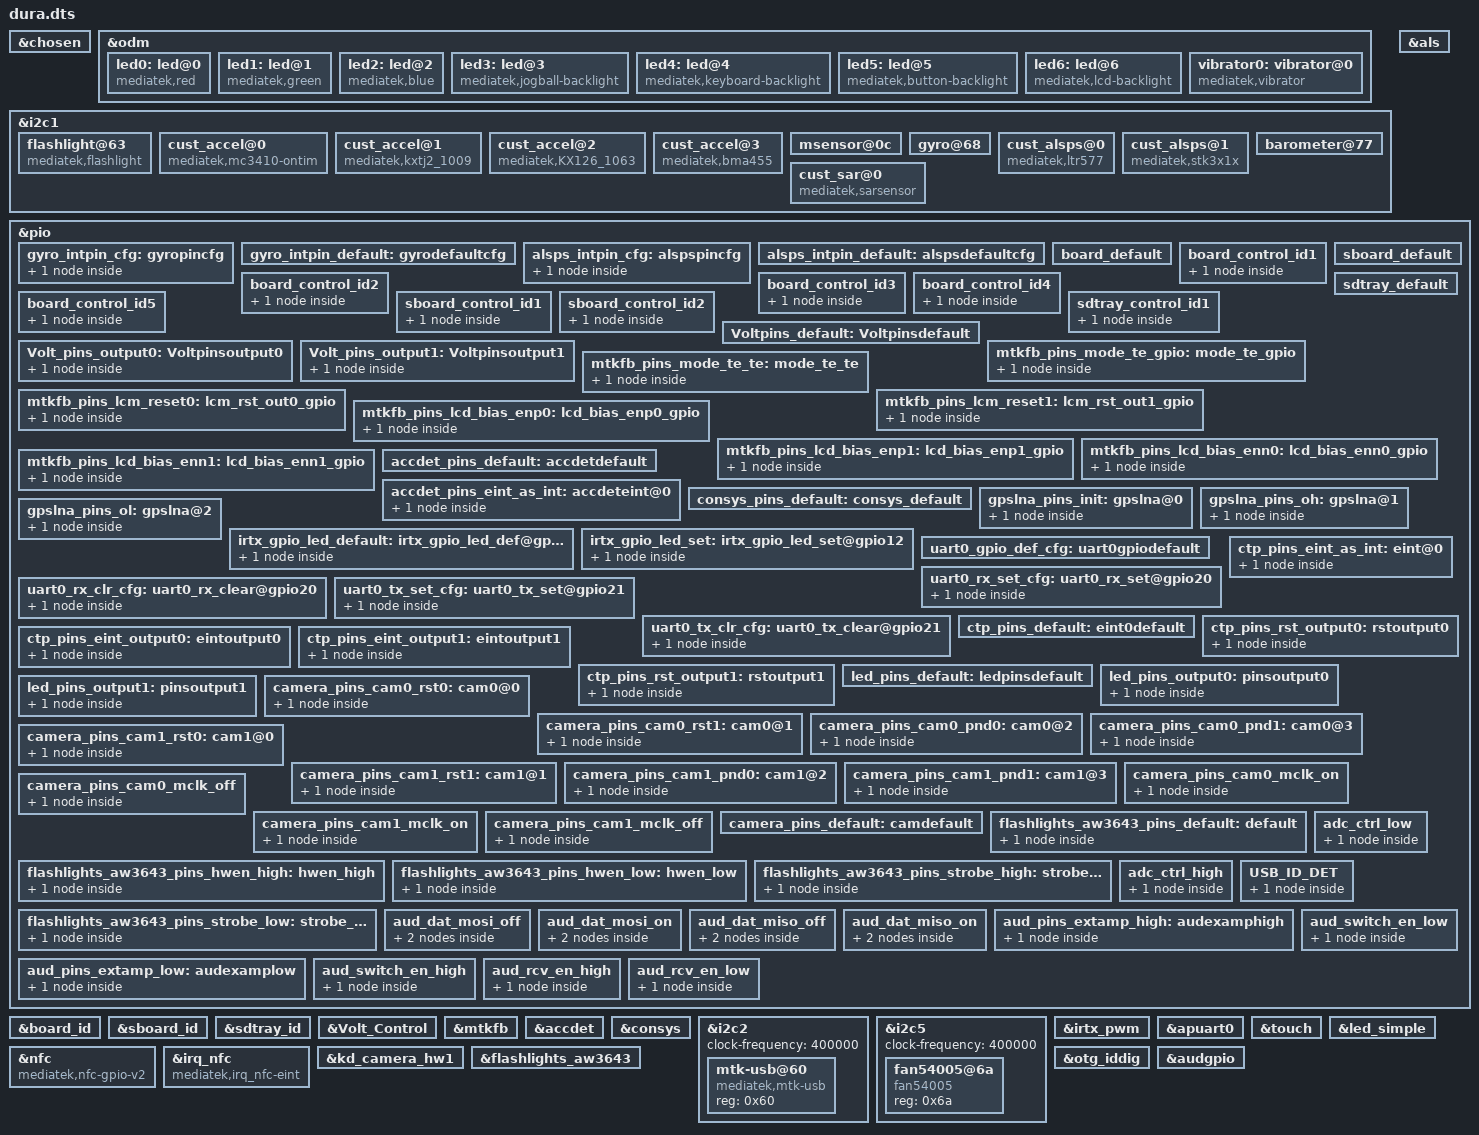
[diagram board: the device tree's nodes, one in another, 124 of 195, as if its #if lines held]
#include <generated/autoconf.h>
/dts-v1/;

#ifdef CONFIG_MTK_DTBO_FEATURE
/plugin/;
#include <dt-bindings/mmc/mt6739-msdc.h>
#include <dt-bindings/pinctrl/mt6739-pinfunc.h>
#else
#include "mt6739.dts"
#endif

/* chosen */
&chosen {
	bootargs = "console=tty0 console=ttyMT0,921600n1 root=/dev/ram initrd=0x44000000,\
0x1000000 loglevel=8 androidboot.selinux=permissive androidboot.hardware=mt6739 initcall_debug=1";
	/* fpga may has no lk, we need to specify display info here */
	/* fb buffer is reserved using this dts by memory node above */

	atag,videolfb-fb_base_l = <0x5e605000>;
	atag,videolfb-fb_base_h = <0>;
	atag,videolfb-islcmfound = <1>;
	atag,videolfb-islcm_inited = <0>;
	atag,videolfb-fps= <6000>;
	atag,videolfb-vramSize= <0x017bb000>;
	atag,videolfb-lcmname= "nt35521_hd_dsi_vdo_truly_nt50358_drv";
};

&odm {
	led0:led@0 {
		compatible = "mediatek,red";
		led_mode = <3>;
		data = <1>;
		pwm_config = <0 0 0 0 0>;
	};
	led1:led@1 {
		compatible = "mediatek,green";
		led_mode = <3>;
		data = <2>;
		pwm_config = <0 0 0 0 0>;
	};
	led2:led@2 {
		compatible = "mediatek,blue";
		led_mode = <0>;
		data = <1>;
		pwm_config = <0 0 0 0 0>;
	};
	led3:led@3 {
		compatible = "mediatek,jogball-backlight";
		led_mode = <0>;
		data = <1>;
		pwm_config = <0 0 0 0 0>;
	};
	led4:led@4 {
		compatible = "mediatek,keyboard-backlight";
		led_mode = <0>;
		data = <1>;
		pwm_config = <0 0 0 0 0>;
	};
	led5:led@5 {
		compatible = "mediatek,button-backlight";
		led_mode = <0>;
		data = <1>;
		pwm_config = <0 0 0 0 0>;
	};
	led6:led@6 {
		compatible = "mediatek,lcd-backlight";
		led_mode = <4>;
		data = <1>;
		pwm_config = <0 0 0 0 0>;
	};
	vibrator0:vibrator@0 {
		compatible = "mediatek,vibrator";
		vib_timer = <25>;
		vib_limit = <9>;
		vib_vol= <11>;
	};
};

&i2c1 {
    flashlight@63 {
		compatible				= "mediatek,flashlight";
		i2c_num				= <1>;
		i2c_addr				= <0x63>;
		};
/*  start sensor */
    cust_accel@0 {
		compatible				= "mediatek,mc3410-ontim";
		i2c_num				= <1>;
		i2c_addr				= <0x4c 0 0 0>;
		direction				= <6>;
		power_id				= <0xffff>;
		power_vol				= <0>;
		firlen					= <0>;
		is_batch_supported			= <0>;
 		calib_enable			= <1>;
		auto_calib_enable			= <0>;
		};
	cust_accel@1 {
        	compatible = "mediatek,kxtj2_1009";
        	i2c_num = <1>;
        	/* i2c_addr = <0x4c 0 0 0>; */
                direction = <4>;
        	power_id = <0xffff>;
        	power_vol = <0>;
        	firlen = <0>;
        	is_batch_supported = <0>;
		calib_enable                    = <1>;
                auto_calib_enable                       = <0>;
        	};
	cust_accel@2 {
                compatible = "mediatek,KX126_1063";
                i2c_num = <1>;
                //i2c_addr = <0x4c 0 0 0>;
                direction = <4>;
                power_id = <0xffff>;
                power_vol = <0>;
                firlen = <0>;
                is_batch_supported = <0>;
        };
	cust_accel@3 {
                compatible = "mediatek,bma455";
                i2c_num = <1>;
                //i2c_addr = <0x4c 0 0 0>;
                direction = <4>;
                power_id = <0xffff>;
                power_vol = <0>;
                firlen = <0>;
                is_batch_supported = <0>;
        	};

	msensor@0c {
		i2c_num = <1>;
		i2c_addr = <0x0d 0 0 0>;
		direction = <8>;
		power_id = <0xffff>;
		power_vol = <0>;
		is_batch_supported = <0>;
	};

	gyro@68 {
		pinctrl-names = "pin_default", "pin_cfg";
		pinctrl-0 = <&gyro_intpin_default>;
		pinctrl-1 = <&gyro_intpin_cfg>;
		i2c_num = <1>;
		i2c_addr = <0x68 0 0 0>;
		direction = <5>;
		power_id = <0xffff>;
		power_vol = <0>;
		firlen = <0>;
		is_batch_supported = <0>;
	};
/*
	alsps@51 {
		pinctrl-names = "pin_default", "pin_cfg";
		pinctrl-0 = <&alsps_intpin_default>;
		pinctrl-1 = <&alsps_intpin_cfg>;
		status = "okay";
		//customization 
		i2c_num = <1>;
		i2c_addr = <0x51 0 0 0>;
		polling_mode_ps = <0>;
		polling_mode_als = <1>;
		power_id = <0xffff>;
		power_vol = <0>;
		als_level = <0 328 861 1377 3125 7721 7767 12621 23062 28430 33274 47116 57694 57694 65535>;
		als_value = <0 133 304 502 1004 2005 3058 5005 8008 10010 12000 16000 20000 20000 20000 20000>;
		ps_threshold_high = <26>;
		ps_threshold_low = <21>;
		is_batch_supported_ps = <0>;
		is_batch_supported_als = <0>;
	};*/

	cust_alsps@0 {
	
		compatible				= "mediatek,ltr577";

		i2c_num	= <1>;
		i2c_addr = <0x53 0 0 0>;
		polling_mode_ps	= <0>;
		polling_mode_als = <1>;
		power_id				= <0xffff>;
		power_vol				= <0>;
		als_level = <  
					0  5   25	52	 102  258  512	650 1000	2000  5000   10000
					0  5   25	52	 102  258  512	650 1000	2000  5000   10000
					0  2   10	20	 40   100  200	310 400	800   2000   4000
					0  11  56	114	 218  546  1109  1610 2000	4000  10000  20000
					0  10  46	100	 192  500  1146 1720 2566	5000  13000  26000
					0  10  57	115	 226  586  1093 1680 2200	4533  10000  20000
					0  10  50	100	 200  500  1000 1600 2000	4000  10000  20000
					0  10  47	81	 170  445  979	1620 2103	3263  10000  20000
					0  10  50	107	 200  480  1000 1600 2000	4000  10000  20000
					 >;
		als_value = < 0  10  50  100  200  500   1000  1600 2000  4000  10000  20000 >;
		ps_threshold_high		=  <900>;
		ps_threshold_low		=  <700>;
		is_batch_supported_ps	= <0>;
		is_batch_supported_als	= <0>;
		};

	cust_alsps@1 {
		compatible				= "mediatek,stk3x1x";
		i2c_num				= <1>;
		i2c_addr				= <0x48 0 0 0>;
		polling_mode_ps			= <0>;
		polling_mode_als		= <1>;
		power_id				= <0xffff>;
		power_vol				= <0>;
		als_level = < 
					0  11  48  97   197  389  481   765   959  1430  1500  2877
					0  12  58  119  223  449  577   963  1169  2116  2829  3507
					0  13  67  137  287  554  690  1065  1317  2015  2635  3951
					0  13  49  101  201  393  490   780   963  1463  1544  2889
					0  12  57  108  222  462  610   964  1185  2053  2749  3555
					0  14  67  143  298  587  719  1155  1405  2137  2732  4215
					0  11  45   92  181  359  448   712   885  1280  1354  2655
					0  12  57  109  201  408  535   894  1085  1761  2355  3255
					0  12  64  137  283  561  684  1043  1272  1998  2499  3816
					>;
		als_value = <0  10  50  100  200  400  500   800  1000  1600  2000  3000>;
		state_val		=  <0>;
		psctrl_val		=  <0x31>;
		alsctrl_val	= <0x39>;
		ledctrl_val	= <0xFF>;
		wait_val		= <0xF>;
		ps_threshold_high		=  <900>;
		ps_threshold_low		=  <700>;
		is_batch_supported_ps	= <0>;
		is_batch_supported_als	= <0>;
		};

	barometer@77 {
		i2c_num = <1>;
		i2c_addr = <0x77 0 0 0>;
		direction = <0>;
		power_id = <0xffff>;
		power_vol = <0>;
		firlen = <32>;
		is_batch_supported = <0>;
	};
	cust_sar@0 {
		compatible				= "mediatek,sarsensor";
		i2c_num				= <1>;
		i2c_addr				= <0x28 0 0 0>;
		};
/* end sensor */
};

&als {
		pinctrl-names = "pin_default", "pin_cfg";
		pinctrl-0 = <&alsps_intpin_default>;
		pinctrl-1 = <&alsps_intpin_cfg>;
		status = "okay";
};
/* sensor gpio standization */
&pio {

	gyro_intpin_cfg: gyropincfg {

	    pins_cmd_dat {
			pins = <PINMUX_GPIO5__FUNC_GPIO5>;
			slew-rate = <0>;
			bias-pull-down = <00>;
		};
	};

	gyro_intpin_default: gyrodefaultcfg {

	};
};

&pio {
	alsps_intpin_cfg: alspspincfg {

		pins_cmd_dat {
			pins = <PINMUX_GPIO1__FUNC_GPIO1>;
			slew-rate = <0>;
			bias-pull-up = <MTK_PUPD_SET_R1R0_01>;
		};
	};

	alsps_intpin_default: alspsdefaultcfg {

	};
};

/* sensor end */
/*Board start*/
&board_id{
id1,intr_gpio = <&pio 121 0x0>;
id2,intr_gpio = <&pio 54 0x0>;
id3,intr_gpio = <&pio 53 0x0>;
id4,intr_gpio = <&pio 5 0x0>;
id5,intr_gpio = <&pio 11 0x0>;
pinctrl-names = "default", "board_id1", "board_id2","board_id3","board_id4","board_id5";
	pinctrl-0 = <&board_default>;
	pinctrl-1 = <&board_control_id1>;
	pinctrl-2 = <&board_control_id2>;
	pinctrl-3 = <&board_control_id3>;
	pinctrl-4 = <&board_control_id4>;
	pinctrl-5 = <&board_control_id5>;
	status = "okay";
};

/* Board GPIO standardization */
&pio {
	board_default: board_default {

    };

	board_control_id1: board_control_id1 {
		pins_cmd_dat {
			pins = <PINMUX_GPIO121__FUNC_GPIO121>;
			slew-rate = <0>;
			bias-disable;
        };
    };

	board_control_id2: board_control_id2 {
		pins_cmd_dat {
			pins = <PINMUX_GPIO54__FUNC_GPIO54>;
			slew-rate = <0>;
			bias-disable;
        };
    };

	board_control_id3: board_control_id3 {
		pins_cmd_dat {
			pins = <PINMUX_GPIO53__FUNC_GPIO53>;
			slew-rate = <0>;
			bias-disable;
        };
    };

	board_control_id4: board_control_id4 {
		pins_cmd_dat {
			pins = <PINMUX_GPIO5__FUNC_GPIO5>;
			slew-rate = <0>;
			bias-disable;
        };
    };

	board_control_id5: board_control_id5 {
		pins_cmd_dat {
			pins = <PINMUX_GPIO11__FUNC_GPIO11>;
			slew-rate = <0>;
			bias-disable;
        };
    };
};
/* Board end */

/*SubBoard start*/
&sboard_id{
sub1,intr_gpio = <&pio 93 0x0>;
sub2,intr_gpio = <&pio 92 0x0>;
pinctrl-names = "default", "sboard_id1", "sboard_id2";
	pinctrl-0 = <&sboard_default>;
	pinctrl-1 = <&sboard_control_id1>;
	pinctrl-2 = <&sboard_control_id2>;
	status = "okay";
};

/* Sub_Board GPIO standardization */
&pio {
	sboard_default: sboard_default {

    };

	sboard_control_id1: sboard_control_id1 {
		pins_cmd_dat {
			pins = <PINMUX_GPIO93__FUNC_GPIO93>;
			slew-rate = <0>;
			bias-disable;
        };
    };

	sboard_control_id2:sboard_control_id2 {
		pins_cmd_dat {
			pins = <PINMUX_GPIO92__FUNC_GPIO92>;
			slew-rate = <0>;
			bias-disable;
        };
    };

};
/* SubBoard end */

/*sdtray start*/
&sdtray_id{
sdtray1,intr_gpio = <&pio 15 0x0>;
pinctrl-names = "default","sdtray_id1";
	pinctrl-0 = <&sdtray_default>;
	pinctrl-1 = <&sdtray_control_id1>;
	status = "okay";
};

&pio {
	sdtray_default:sdtray_default{

	};
	sdtray_control_id1:sdtray_control_id1{
		pins_cmd_dat {
			pins = <PINMUX_GPIO15__FUNC_GPIO15>;
			slew-rate = <0>;
			bias-disable;
		};
	};
};
/*sdtray end*/

/*Voltage Control Start*/
&Volt_Control{
	pinctrl-names = "default","Volt_output0","Volt_output1";
	pinctrl-0 = <&Voltpins_default>;
	pinctrl-1 = <&Volt_pins_output0>;
	pinctrl-2 = <&Volt_pins_output1>;
	status = "okay";
};

&pio {
	Voltpins_default: Voltpinsdefault {
	};
	Volt_pins_output0: Voltpinsoutput0 {
		pins_cmd_dat {
			pins = <PINMUX_GPIO95__FUNC_GPIO95>;
			slew_rate = <1>;
			output-low;
		};
	};
	Volt_pins_output1: Voltpinsoutput1 {
		pins_cmd_dat {
			pins = <PINMUX_GPIO95__FUNC_GPIO95>;
			slew_rate = <1>;
			output-high;
		};
	};
};
/*Voltage Control End*/
/* DISPSYS GPIO standardization */
&pio {
	mtkfb_pins_mode_te_gpio: mode_te_gpio {
		pins_cmd_dat {
			pins = <PINMUX_GPIO84__FUNC_DSI_TE>;
		};
	};

	mtkfb_pins_mode_te_te: mode_te_te {
		pins_cmd_dat {
			pins = <PINMUX_GPIO84__FUNC_DSI_TE>;
		};
	};

	mtkfb_pins_lcm_reset0: lcm_rst_out0_gpio {
		pins_cmd_dat {
			pins = <PINMUX_GPIO83__FUNC_GPIO83>;
			slew-rate = <1>;
			output-low;
		};
	};

	mtkfb_pins_lcm_reset1: lcm_rst_out1_gpio {
		pins_cmd_dat {
			pins = <PINMUX_GPIO83__FUNC_GPIO83>;
			slew-rate = <1>;
			output-high;
		};
	};

	mtkfb_pins_lcd_bias_enp0: lcd_bias_enp0_gpio {
		pins_cmd_dat {
			pins = <PINMUX_GPIO122__FUNC_GPIO122>;
			slew-rate = <1>;
			output-low;
		};
	};
	mtkfb_pins_lcd_bias_enp1: lcd_bias_enp1_gpio {
		pins_cmd_dat {
			pins = <PINMUX_GPIO122__FUNC_GPIO122>;
			slew-rate = <1>;
			output-high;
		};
	};
	mtkfb_pins_lcd_bias_enn0: lcd_bias_enn0_gpio {
		pins_cmd_dat {
			pins = <PINMUX_GPIO112__FUNC_GPIO112>;
			slew-rate = <1>;
			output-low;
		};
	};
	mtkfb_pins_lcd_bias_enn1: lcd_bias_enn1_gpio {
		pins_cmd_dat {
			pins = <PINMUX_GPIO112__FUNC_GPIO112>;
			slew-rate = <1>;
			output-high;
		};
	};

};

&mtkfb {
	pinctrl-names = "mode_te_gpio", "mode_te_te", "lcm_rst_out0_gpio",
		"lcm_rst_out1_gpio", "lcd_bias_enp0_gpio", "lcd_bias_enp1_gpio", "lcd_bias_enn0_gpio", "lcd_bias_enn1_gpio";
	pinctrl-0 = <&mtkfb_pins_mode_te_gpio>;
	pinctrl-1 = <&mtkfb_pins_mode_te_te>;
	pinctrl-2 = <&mtkfb_pins_lcm_reset0>;
	pinctrl-3 = <&mtkfb_pins_lcm_reset1>;
	pinctrl-4 = <&mtkfb_pins_lcd_bias_enp0>;
	pinctrl-5 = <&mtkfb_pins_lcd_bias_enp1>;
	pinctrl-6 = <&mtkfb_pins_lcd_bias_enn0>;
	pinctrl-7 = <&mtkfb_pins_lcd_bias_enn1>;
	status = "okay";
};
/* DISPSYS GPIO standardization end */


/* accdet start */
&accdet {
	/* accdet micbias voltage: 0x07,2.7v;0x05,2.5v;0x02,1.9v */
	accdet-mic-vol = <7>;
	headset-mode-setting = <0x500 0x500 1 0x1f0 0x800 0x800 0x20 0x44>;
	accdet-plugout-debounce = <1>;
	/*1:ACC mode, 2:low cost without in bias, 6:low cost with in bias*/
	accdet-mic-mode = <1>;
	/* eint_level_trigger: 8,LEVEL_LOW(default);4,LEVEL_HIGH;others,LEVEL_LOW */
	headset-eint-level-pol = <8>;
	/*0--MD_MAX--UP_MAX--DW_MAX*/
	headset-three-key-threshold = <0 80 220 447>;
	headset-three-key-threshold-CDD = <0 121 192 600>;
	/*0--MD_MAX--VOICE_MAX--UP_MAX--DW_MAX*/
	headset-four-key-threshold = <0 58 121 192 400>;
	/* ACCDET GPIO standardization ACC mode no use */
	pinctrl-names = "default", "state_eint_as_int";
	pinctrl-0 = <&accdet_pins_default>;
	pinctrl-1 = <&accdet_pins_eint_as_int>;
	status = "okay";
};
&pio {
	accdet_pins_default: accdetdefault {
	};
	accdet_pins_eint_as_int: accdeteint@0 {
		pins_cmd_dat {
			/*pins = <PINMUX_GPIO11__FUNC_GPIO11>;*/
			slew-rate = <0>;
			bias-disable;
		};
	};
};
/* accdet end */
/* CONSYS GPIO standardization */
&pio {
	consys_pins_default: consys_default {
	};
	gpslna_pins_init: gpslna@0 {
		pins_cmd_dat {
			pins = <PINMUX_GPIO118__FUNC_GPIO118>;
			slew-rate = <0>;
			bias-disable;
			output-low;
		};
	};
	gpslna_pins_oh: gpslna@1 {
		pins_cmd_dat {
			pins = <PINMUX_GPIO118__FUNC_GPIO118>;
			slew-rate = <1>;
			output-high;
		};
	};
	gpslna_pins_ol: gpslna@2 {
		pins_cmd_dat {
			pins = <PINMUX_GPIO118__FUNC_GPIO118>;
			slew-rate = <1>;
			output-low;
		};
	};
};
&consys {
	pinctrl-names = "default", "gps_lna_state_init", "gps_lna_state_oh", "gps_lna_state_ol";
	pinctrl-0 = <&consys_pins_default>;
	pinctrl-1 = <&gpslna_pins_init>;
	pinctrl-2 = <&gpslna_pins_oh>;
	pinctrl-3 = <&gpslna_pins_ol>;
	status = "okay";
};
&i2c2 {
	#address-cells = <1>;
	#size-cells = <0>;
	clock-frequency = <400000>;

	mtk-usb@60 {
		compatible = "mediatek,mtk-usb";
		reg = <0x60>;
		status = "okay";
	};
};
&i2c5 {
	#address-cells = <1>;
	#size-cells = <0>;
	clock-frequency = <400000>;

	fan54005@6a {
		compatible = "fan54005";
		reg = <0x6a>;
		status = "okay";
	};
};

/* IRTX GPIO Start */
&irtx_pwm {
	pinctrl-names = "irtx_gpio_led_default", "irtx_gpio_led_set";
	pinctrl-0 = <&irtx_gpio_led_default>;
	pinctrl-1 = <&irtx_gpio_led_set>;
	status = "okay";
};
&pio {
	/* IRTX GPIO Settings -Start */
	/* default: GPIO0, output, high */
	irtx_gpio_led_default:irtx_gpio_led_def@gpio12 {
		pins_cmd_dat {
			pins = <PINMUX_GPIO12__FUNC_GPIO12>;
			slew-rate = <1>;
			bias-disable;
			output-low;
			input-schmitt-enable = <0>;
		};
	};

	irtx_gpio_led_set:irtx_gpio_led_set@gpio12 {
		pins_cmd_dat {
			pins = <PINMUX_GPIO12__FUNC_PWM1>;
			slew-rate = <1>;
			output-high;
		};
	};
}; /* IRTX GPIO Settings -End */

/* UART GPIO */
&apuart0 {
	pinctrl-names = "uart0_gpio_default",
			"uart0_rx_set",
			"uart0_rx_clear",
			"uart0_tx_set",
			"uart0_tx_clear";
	pinctrl-0 = <&uart0_gpio_def_cfg>;
	pinctrl-1 = <&uart0_rx_set_cfg>;
	pinctrl-2 = <&uart0_rx_clr_cfg>;
	pinctrl-3 = <&uart0_tx_set_cfg>;
	pinctrl-4 = <&uart0_tx_clr_cfg>;
	status = "okay";
};

&pio {
	/* UART GPIO Settings - Start */
	/* UART0: rx set, rx clear, tx clear, tx clear*/
	uart0_gpio_def_cfg:uart0gpiodefault {

	};
	uart0_rx_set_cfg:uart0_rx_set@gpio20 {
		pins_cmd_dat {
			pins = <PINMUX_GPIO20__FUNC_UART0RX>;
		};
	};
	uart0_rx_clr_cfg:uart0_rx_clear@gpio20 {
		pins_cmd_dat {
			pins = <PINMUX_GPIO20__FUNC_GPIO20>;
			slew-rate = <1>;
			output-high;
		};
	};
	uart0_tx_set_cfg:uart0_tx_set@gpio21 {
		pins_cmd_dat {
			pins = <PINMUX_GPIO21__FUNC_UART0TX>;
		};
	};
	uart0_tx_clr_cfg:uart0_tx_clear@gpio21 {
		pins_cmd_dat {
			pins = <PINMUX_GPIO21__FUNC_GPIO21>;
			slew-rate = <1>;
			output-high;
		};
	};
};/* UART GPIO end */

/* TOUCH start */
&touch {
	tpd-resolution = <720 1280>;
	use-tpd-button = <0>;
	tpd-key-num = <3>;
	tpd-key-local= <139 172 158 0>;
	tpd-key-dim-local = <90 883 100 40 230 883 100 40 370 883 100 40 0 0 0 0>;
	tpd-max-touch-num = <5>;
	tpd-filter-enable = <1>;
	tpd-filter-pixel-density = <106>;
	tpd-filter-custom-prameters = <0 0 0 0 0 0 0 0 0 0 0 0>;
	tpd-filter-custom-speed = <0 0 0>;
	pinctrl-names = "default", "state_eint_as_int", "state_eint_output0", "state_eint_output1",
		"state_rst_output0", "state_rst_output1";
	pinctrl-0 = <&ctp_pins_default>;
	pinctrl-1 = <&ctp_pins_eint_as_int>;
	pinctrl-2 = <&ctp_pins_eint_output0>;
	pinctrl-3 = <&ctp_pins_eint_output1>;
	pinctrl-4 = <&ctp_pins_rst_output0>;
	pinctrl-5 = <&ctp_pins_rst_output1>;
	status = "okay";
};
&pio {
	ctp_pins_default: eint0default {
	};
	ctp_pins_eint_as_int: eint@0 {
		pins_cmd_dat {
			pins = <PINMUX_GPIO6__FUNC_GPIO6>;
			slew-rate = <0>;
			bias-disable;
		};
	};
	ctp_pins_eint_output0: eintoutput0 {
		pins_cmd_dat {
			pins = <PINMUX_GPIO6__FUNC_GPIO6>;
			slew-rate = <1>;
			output-low;
		};
	};
	ctp_pins_eint_output1: eintoutput1 {
		pins_cmd_dat {
			pins = <PINMUX_GPIO6__FUNC_GPIO6>;
			slew-rate = <1>;
			output-high;
		};
	};
	ctp_pins_rst_output0: rstoutput0 {
		pins_cmd_dat {
			pins = <PINMUX_GPIO119__FUNC_GPIO119>;
			slew-rate = <1>;
			output-low;
		};
	};
	ctp_pins_rst_output1: rstoutput1 {
		pins_cmd_dat {
			pins = <PINMUX_GPIO119__FUNC_GPIO119>;
			slew-rate = <1>;
			output-high;
		};
	};
};
/* TOUCH end */
/* leds start */
&led_simple {
	pinctrl-names = "default", "led_output0", "led_output1";
	pinctrl-0 = <&led_pins_default>;
	pinctrl-1 = <&led_pins_output0>;
	pinctrl-2 = <&led_pins_output1>;
	status = "okay";
};
&pio {
	led_pins_default: ledpinsdefault {
	};
	led_pins_output0: pinsoutput0 {
		pins_cmd_dat {
			pins = <PINMUX_GPIO94__FUNC_GPIO94>;
			slew-rate = <1>;
			output-low;
		};
	};
	led_pins_output1: pinsoutput1 {
		pins_cmd_dat {
			pins = <PINMUX_GPIO94__FUNC_GPIO94>;
			slew-rate = <1>;
			output-high;
		};
	};
};
/* leds end */
/* NFC start */
&nfc {
	compatible = "mediatek,nfc-gpio-v2";
	gpio-rst = <7>;
	gpio-rst-std = <&pio 7 0x0>;
	gpio-irq = <14>;
	gpio-irq-std = <&pio 14 0x0>;
};

&irq_nfc {
	compatible = "mediatek,irq_nfc-eint";
};
/* NFC end */

/* CAMERA GPIO standardization */
&pio {
	camera_pins_cam0_rst0: cam0@0 {
		pins_cmd_dat {
			pins = <PINMUX_GPIO29__FUNC_GPIO29>;
			slew-rate = <1>; /*direction 0:in, 1:out*/
			output-low;/*direction out used only. output_low or high*/
		};
	};
	camera_pins_cam0_rst1: cam0@1 {
		pins_cmd_dat {
			pins = <PINMUX_GPIO29__FUNC_GPIO29>;
			slew-rate = <1>;
			output-high;
		};
	};
	camera_pins_cam0_pnd0: cam0@2 {
		pins_cmd_dat {
			pins = <PINMUX_GPIO30__FUNC_GPIO30>;
			slew-rate = <1>;
			output-low;
		};
	};
	camera_pins_cam0_pnd1: cam0@3 {
		pins_cmd_dat {
			pins = <PINMUX_GPIO30__FUNC_GPIO30>;
			slew-rate = <1>;
			output-high;
		};
	};
	camera_pins_cam1_rst0: cam1@0 {
		pins_cmd_dat {
			pins = <PINMUX_GPIO22__FUNC_GPIO22>;
			slew-rate = <1>; /*direction 0:in, 1:out*/
			output-low;/*direction out used only. output_low or high*/
		};
	};
	camera_pins_cam1_rst1: cam1@1 {
		pins_cmd_dat {
			pins = <PINMUX_GPIO22__FUNC_GPIO22>;
			slew-rate = <1>;
			output-high;
		};
	};
	camera_pins_cam1_pnd0: cam1@2 {
		pins_cmd_dat {
			pins = <PINMUX_GPIO23__FUNC_GPIO23>;
			slew-rate = <1>;
			output-low;
		};
	};
	camera_pins_cam1_pnd1: cam1@3 {
		pins_cmd_dat {
			pins = <PINMUX_GPIO23__FUNC_GPIO23>;
			slew-rate = <1>;
			output-high;
		};
	};
/*	camera_pins_cam_ldo_sub_vcamd_0: cam1@vcamd0 {
		pins_cmd_dat {
			pins = <PINMUX_GPIO9__FUNC_GPIO9>;
			slew-rate = <1>;
			output-low;
		};
	};
	camera_pins_cam_ldo_sub_vcamd_1: cam1@vcamd1 {
		pins_cmd_dat {
			pins = <PINMUX_GPIO9__FUNC_GPIO9>;
			slew-rate = <1>;
			output-high;
		};
	};
*/
	camera_pins_cam0_mclk_on: camera_pins_cam0_mclk_on {
		pins_cmd_dat {
			pins = <PINMUX_GPIO126__FUNC_CMMCLK0>;
		};
	};
	camera_pins_cam0_mclk_off: camera_pins_cam0_mclk_off {
		pins_cmd_dat {
			pins = <PINMUX_GPIO126__FUNC_GPIO126>;
		};
	};
	camera_pins_cam1_mclk_on: camera_pins_cam1_mclk_on {
		pins_cmd_dat {
			pins = <PINMUX_GPIO126__FUNC_CMMCLK0>;
		};
	};
	camera_pins_cam1_mclk_off: camera_pins_cam1_mclk_off {
		pins_cmd_dat {
			pins = <PINMUX_GPIO126__FUNC_GPIO126>;
		};
	};
	camera_pins_default: camdefault {
	};
};

&kd_camera_hw1 {
	pinctrl-names = "default",
			"cam0_rst0", "cam0_rst1", "cam0_pnd0", "cam0_pnd1",
			"cam1_rst0", "cam1_rst1", "cam1_pnd0", "cam1_pnd1",
			"cam0_mclk_on", "cam0_mclk_off",
			"cam1_mclk_on", "cam1_mclk_off";

	pinctrl-0 = <&camera_pins_default>;
	pinctrl-1 = <&camera_pins_cam0_rst0>;
	pinctrl-2 = <&camera_pins_cam0_rst1>;
	pinctrl-3 = <&camera_pins_cam0_pnd0>;
	pinctrl-4 = <&camera_pins_cam0_pnd1>;
	pinctrl-5 = <&camera_pins_cam1_rst0>;
	pinctrl-6 = <&camera_pins_cam1_rst1>;
	pinctrl-7 = <&camera_pins_cam1_pnd0>;
	pinctrl-8 = <&camera_pins_cam1_pnd1>;

	pinctrl-11 = <&camera_pins_cam0_mclk_on>;
	pinctrl-12 = <&camera_pins_cam0_mclk_off>;
	pinctrl-13 = <&camera_pins_cam1_mclk_on>;
	pinctrl-14 = <&camera_pins_cam1_mclk_off>;
	status = "okay";

};
/* CAMERA GPIO end */

 /*FLASHLIGHT GPIO standardization*/
&pio{
    flashlights_aw3643_pins_default: default{
	pins_cmd_dat{
		pins = <PINMUX_GPIO10__FUNC_GPIO10>;
		slew-rate = <1>;
		output-high;
		};
	};
	flashlights_aw3643_pins_hwen_high: hwen_high{
	pins_cmd_dat{
		pins = <PINMUX_GPIO10__FUNC_GPIO10>;
		slew-rate = <1>;
		output-high;
		};
	};
	flashlights_aw3643_pins_hwen_low: hwen_low{
	pins_cmd_dat{
		pins = <PINMUX_GPIO10__FUNC_GPIO10>;
		slew-rate = <1>;
		output-low;
		};
	};
	flashlights_aw3643_pins_strobe_high: strobe_high{
	pins_cmd_dat{
		pins = <PINMUX_GPIO3__FUNC_GPIO3>;
		slew-rate = <1>;
		output-high;
		};
	};
	flashlights_aw3643_pins_strobe_low: strobe_low{
	pins_cmd_dat{
		pins = <PINMUX_GPIO3__FUNC_GPIO3>;
		slew-rate = <1>;
		output-low;
		};
	};
};
&flashlights_aw3643{
    pinctrl-names = "default","hwen_high","hwen_low","strobe_high","strobe_low";
    pinctrl-0 = <&flashlights_aw3643_pins_default>;
	pinctrl-1 = <&flashlights_aw3643_pins_hwen_high>;
	pinctrl-2 = <&flashlights_aw3643_pins_hwen_low>;
	pinctrl-3 = <&flashlights_aw3643_pins_strobe_high>;
	pinctrl-4 = <&flashlights_aw3643_pins_strobe_low>;
	status = "okay";
};
/* FLASHLIGHT GPIO end */
/*OTG ADC_CTRL begin!*/
&pio {
    adc_ctrl_low: adc_ctrl_low {
        pins_cmd_dat {
            pins = <PINMUX_GPIO95__FUNC_GPIO95>;
            slew-rate = <1>;
            output-low;
        };
    };
    adc_ctrl_high: adc_ctrl_high {
        pins_cmd_dat {
            pins = <PINMUX_GPIO95__FUNC_GPIO95>;
            slew-rate = <1>;
            output-high;
        };
    };
USB_ID_DET: USB_ID_DET {
    pins_cmd_dat {
            pins = <PINMUX_GPIO7__FUNC_GPIO7>;
            slew-rate = <0>;
            bias-disable;
        };
    };
};
&otg_iddig{
usb,eint_gpio = <&pio 7 0x0>;
pinctrl-names =  "adc_ctrl_low","adc_ctrl_high","USB_ID_DET";
    pinctrl-0 = <&adc_ctrl_low>;
    pinctrl-1 = <&adc_ctrl_high>;
    pinctrl-2 = <&USB_ID_DET>;
    status = "okay";
};
/*OTG ADC_CTRL end!*/
/* AUDIO GPIO standardization */
&audgpio {
	pinctrl-names = "aud_dat_mosi_off",
			"aud_dat_mosi_on",
			"aud_dat_miso_off",
			"aud_dat_miso_on",
			"extamp-pullhigh",
			"extamp-pulllow",
			"aud_switch_en_high",
			"aud_switch_en_low",
			"aud_rcv_en_high",
			"aud_rcv_en_low";
	pinctrl-0 = <&aud_dat_mosi_off>;
	pinctrl-1 = <&aud_dat_mosi_on>;
	pinctrl-2 = <&aud_dat_miso_off>;
	pinctrl-3 = <&aud_dat_miso_on>;
	pinctrl-4 = <&aud_pins_extamp_high>;
	pinctrl-5 = <&aud_pins_extamp_low>;
	pinctrl-6 = <&aud_switch_en_high>;
	pinctrl-7 = <&aud_switch_en_low>;
	pinctrl-8 = <&aud_rcv_en_high>;
	pinctrl-9 = <&aud_rcv_en_low>;
	status = "okay";
};

&pio {
	aud_dat_mosi_off: aud_dat_mosi_off {
		pins_cmd1_dat {
			pins = <PINMUX_GPIO63__FUNC_GPIO63>;
			input-enable;
			slew-rate = <0>;
			bias-disable;
		};
		pins_cmd2_dat {
			pins = <PINMUX_GPIO64__FUNC_GPIO64>;
			input-enable;
			slew-rate = <0>;
			bias-disable;
		};
	};

	aud_dat_mosi_on: aud_dat_mosi_on {
		pins_cmd1_dat {
			pins = <PINMUX_GPIO63__FUNC_AUD_DAT_MOSI0>;
		};
		pins_cmd2_dat {
			pins = <PINMUX_GPIO64__FUNC_AUD_DAT_MOSI1>;
		};
	};

	aud_dat_miso_off: aud_dat_miso_off {
		pins_cmd1_dat {
			pins = <PINMUX_GPIO67__FUNC_GPIO67>;
			input-enable;
			slew-rate = <0>;
			bias-disable;
		};
		pins_cmd2_dat {
			pins = <PINMUX_GPIO68__FUNC_GPIO68>;
			input-enable;
			slew-rate = <0>;
			bias-disable;
		};
	};

	aud_dat_miso_on: aud_dat_miso_on {
		pins_cmd1_dat {
			pins = <PINMUX_GPIO67__FUNC_AUD_DAT_MISO0>;
		};
		pins_cmd2_dat {
			pins = <PINMUX_GPIO68__FUNC_AUD_DAT_MISO1>;
		};
	};
	aud_pins_extamp_high: audexamphigh {
		pins_cmd_dat {
			pins = <PINMUX_GPIO24__FUNC_GPIO24>;
			slew-rate = <1>;
			output-high;
		};
	};

	aud_pins_extamp_low: audexamplow {
		pins_cmd_dat {
			pins = <PINMUX_GPIO24__FUNC_GPIO24>;
			slew-rate = <1>;
			output-low;
		};
	};

	aud_switch_en_high: aud_switch_en_high {
		pins_cmd_dat {
			pins = <PINMUX_GPIO31__FUNC_GPIO31>;
			slew-rate = <1>;
			output-high;
		};
	};
	aud_switch_en_low: aud_switch_en_low {
		pins_cmd_dat {
			pins = <PINMUX_GPIO31__FUNC_GPIO31>;
			slew-rate = <1>;
			output-low;
		};
	};

	aud_rcv_en_high: aud_rcv_en_high {
		pins_cmd_dat {
			pins = <PINMUX_GPIO32__FUNC_GPIO32>;
			slew-rate = <1>;
			output-high;
		};
	};
	aud_rcv_en_low: aud_rcv_en_low {
		pins_cmd_dat {
			pins = <PINMUX_GPIO32__FUNC_GPIO32>;
			slew-rate = <1>;
			output-low;
		};
	};
};
/* AUDIO end */

#include <dura/cust.dtsi>
/*End of this file, DO NOT ADD ANYTHING HERE*/
